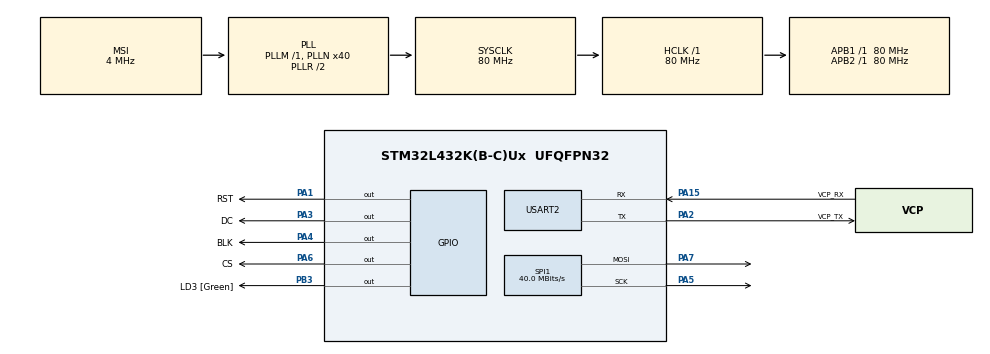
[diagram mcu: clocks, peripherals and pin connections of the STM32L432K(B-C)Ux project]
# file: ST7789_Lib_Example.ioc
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FREERTOS.Tasks01=defaultTask,24,128,StartDefaultTask,Default,NULL,Dynamic,NULL,NULL
FREERTOS.configENABLE_FPU=1
Mcu.Family=STM32L4
Mcu.Name=STM32L432K(B-C)Ux
Mcu.Package=UFQFPN32
NVIC.PriorityGroup=NVIC_PRIORITYGROUP_4
NVIC.TIM1_UP_TIM16_IRQn=true\:15\:0\:false\:false\:true\:false\:false\:true\:true
NVIC.TimeBase=TIM1_UP_TIM16_IRQn
NVIC.TimeBaseIP=TIM1
PA0.GPIO_Label=MCO [High speed clock in]
PA0.Mode=HSE-External-Clock-Source-for-LittleOrca
PA0.Signal=RCC_CK_IN
PA1.GPIO_Label=RST
PA1.Signal=GPIO_Output
PA13\ (JTMS-SWDIO).GPIO_Label=SWDIO
PA13\ (JTMS-SWDIO).Mode=Serial_Wire
PA13\ (JTMS-SWDIO).Signal=SYS_JTMS-SWDIO
PA14\ (JTCK-SWCLK).GPIO_Label=SWCLK
PA14\ (JTCK-SWCLK).Mode=Serial_Wire
PA14\ (JTCK-SWCLK).Signal=SYS_JTCK-SWCLK
PA15\ (JTDI).GPIO_Label=VCP_RX
PA15\ (JTDI).Mode=Asynchronous
PA15\ (JTDI).Signal=USART2_RX
PA2.GPIO_Label=VCP_TX
PA2.Mode=Asynchronous
PA2.Signal=USART2_TX
PA3.GPIO_Label=DC
PA3.Signal=GPIO_Output
PA4.GPIO_Label=BLK
PA4.Signal=GPIO_Output
PA5.Mode=TX_Only_Simplex_Unidirect_Master
PA5.Signal=SPI1_SCK
PA6.GPIO_Label=CS
PA6.Signal=GPIO_Output
PA7.Mode=TX_Only_Simplex_Unidirect_Master
PA7.Signal=SPI1_MOSI
PB3\ (JTDO-TRACESWO).GPIO_Label=LD3 [Green]
PB3\ (JTDO-TRACESWO).Signal=GPIO_Output
PC14-OSC32_IN\ (PC14).Mode=LSE-External-Oscillator
PC14-OSC32_IN\ (PC14).Signal=RCC_OSC32_IN
PC15-OSC32_OUT\ (PC15).Mode=LSE-External-Oscillator
PC15-OSC32_OUT\ (PC15).Signal=RCC_OSC32_OUT
ProjectManager.HeapSize=0x200
ProjectManager.StackSize=0x400
ProjectManager.TargetToolchain=STM32CubeIDE
RCC.ADCFreq_Value=16000000
RCC.AHBFreq_Value=80000000
RCC.APB1Freq_Value=80000000
RCC.APB1TimFreq_Value=80000000
RCC.APB2Freq_Value=80000000
RCC.APB2TimFreq_Value=80000000
RCC.CortexFreq_Value=80000000
RCC.HCLKFreq_Value=80000000
RCC.HSE_VALUE=8000000
RCC.HSI16_VALUE=16000000
RCC.HSI48_VALUE=48000000
RCC.HSI_VALUE=16000000
RCC.MSI_VALUE=4000000
RCC.PLLMUL=RCC_PLLMUL_4
RCC.PLLN=40
RCC.SYSCLKFreq_VALUE=80000000
RCC.SYSCLKSource=RCC_SYSCLKSOURCE_PLLCLK
RCC.USBFreq_Value=16000000
RCC.VCOOutputFreq_Value=160000000
RTC.Date=2
RTC.Month=RTC_MONTH_FEBRUARY
RTC.Year=24
SPI1.BaudRatePrescaler=SPI_BAUDRATEPRESCALER_2
SPI1.CLKPhase=SPI_PHASE_2EDGE
SPI1.CLKPolarity=SPI_POLARITY_HIGH
SPI1.CalculateBaudRate=40.0 MBits/s
SPI1.DataSize=SPI_DATASIZE_8BIT
SPI1.Direction=SPI_DIRECTION_2LINES
SPI1.Mode=SPI_MODE_MASTER
SPI1.VirtualType=VM_MASTER
USART2.VirtualMode-Asynchronous=VM_ASYNC
VP_FREERTOS_VS_CMSIS_V2.Mode=CMSIS_V2
VP_RTC_VS_RTC_Activate.Mode=RTC_Enabled
VP_RTC_VS_RTC_Calendar.Mode=RTC_Calendar
VP_SYS_VS_tim1.Mode=TIM1
board=NUCLEO-L432KC

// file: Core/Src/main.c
/* USER CODE BEGIN Header */
/**
  ******************************************************************************
  * @file           : main.c
  * @brief          : Main program body
  ******************************************************************************
  * @attention
  *
  * Copyright (c) 2024 STMicroelectronics.
  * All rights reserved.
  *
  * This software is licensed under terms that can be found in the LICENSE file
  * in the root directory of this software component.
  * If no LICENSE file comes with this software, it is provided AS-IS.
  *
  ******************************************************************************
  */
/* USER CODE END Header */
#include "main.h"
#include "cmsis_os.h"

/* USER CODE BEGIN Includes */
#include <Interface_ST7789.h>
#include <ST7789.h>
/* USER CODE END Includes */

RTC_HandleTypeDef hrtc;

SPI_HandleTypeDef hspi1;

UART_HandleTypeDef huart2;

/* Definitions for defaultTask */
osThreadId_t defaultTaskHandle;
const osThreadAttr_t defaultTask_attributes = {
  .name = "defaultTask",
  .stack_size = 128 * 4,
  .priority = (osPriority_t) osPriorityNormal,
};

void SystemClock_Config(void);
static void MX_GPIO_Init(void);
static void MX_USART2_UART_Init(void);
static void MX_RTC_Init(void);
static void MX_SPI1_Init(void);
void StartDefaultTask(void *argument);

int main(void)
{

  /* MCU Configuration--------------------------------------------------------*/

  /* Reset of all peripherals, Initializes the Flash interface and the Systick. */
  HAL_Init();

  /* Configure the system clock */
  SystemClock_Config();

  /* Initialize all configured peripherals */
  MX_GPIO_Init();
  MX_USART2_UART_Init();
  MX_RTC_Init();
  MX_SPI1_Init();
  /* USER CODE BEGIN 2 */
  ST7789_Init();
  ST7789_Clear();
  ST7789_FillScreen(ST7789_WHITE);
  osDelay(1000);

  /* USER CODE END 2 */

  /* Init scheduler */
  osKernelInitialize();

  /* Create the thread(s) */
  /* creation of defaultTask */
  defaultTaskHandle = osThreadNew(StartDefaultTask, NULL, &defaultTask_attributes);

  /* Start scheduler */
  osKernelStart();

  /* We should never get here as control is now taken by the scheduler */
  /* Infinite loop */
  while (1)
  {

  }
}

void SystemClock_Config(void)
{
  RCC_OscInitTypeDef RCC_OscInitStruct = {0};
  RCC_ClkInitTypeDef RCC_ClkInitStruct = {0};

  /** Configure the main internal regulator output voltage
  */
  if (HAL_PWREx_ControlVoltageScaling(PWR_REGULATOR_VOLTAGE_SCALE1) != HAL_OK)
  {
    Error_Handler();
  }

  /** Configure LSE Drive Capability
  */
  HAL_PWR_EnableBkUpAccess();
  __HAL_RCC_LSEDRIVE_CONFIG(RCC_LSEDRIVE_LOW);

  /** Initializes the RCC Oscillators according to the specified parameters
  * in the RCC_OscInitTypeDef structure.
  */
  RCC_OscInitStruct.OscillatorType = RCC_OSCILLATORTYPE_LSI|RCC_OSCILLATORTYPE_LSE
                              |RCC_OSCILLATORTYPE_MSI;
  RCC_OscInitStruct.LSEState = RCC_LSE_ON;
  RCC_OscInitStruct.LSIState = RCC_LSI_ON;
  RCC_OscInitStruct.MSIState = RCC_MSI_ON;
  RCC_OscInitStruct.MSICalibrationValue = 0;
  RCC_OscInitStruct.MSIClockRange = RCC_MSIRANGE_6;
  RCC_OscInitStruct.PLL.PLLState = RCC_PLL_ON;
  RCC_OscInitStruct.PLL.PLLSource = RCC_PLLSOURCE_MSI;
  RCC_OscInitStruct.PLL.PLLM = 1;
  RCC_OscInitStruct.PLL.PLLN = 40;
  RCC_OscInitStruct.PLL.PLLP = RCC_PLLP_DIV7;
  RCC_OscInitStruct.PLL.PLLQ = RCC_PLLQ_DIV2;
  RCC_OscInitStruct.PLL.PLLR = RCC_PLLR_DIV2;
  if (HAL_RCC_OscConfig(&RCC_OscInitStruct) != HAL_OK)
  {
    Error_Handler();
  }

  /** Initializes the CPU, AHB and APB buses clocks
  */
  RCC_ClkInitStruct.ClockType = RCC_CLOCKTYPE_HCLK|RCC_CLOCKTYPE_SYSCLK
                              |RCC_CLOCKTYPE_PCLK1|RCC_CLOCKTYPE_PCLK2;
  RCC_ClkInitStruct.SYSCLKSource = RCC_SYSCLKSOURCE_PLLCLK;
  RCC_ClkInitStruct.AHBCLKDivider = RCC_SYSCLK_DIV1;
  RCC_ClkInitStruct.APB1CLKDivider = RCC_HCLK_DIV1;
  RCC_ClkInitStruct.APB2CLKDivider = RCC_HCLK_DIV1;

  if (HAL_RCC_ClockConfig(&RCC_ClkInitStruct, FLASH_LATENCY_4) != HAL_OK)
  {
    Error_Handler();
  }

  /** Enable MSI Auto calibration
  */
  HAL_RCCEx_EnableMSIPLLMode();
}

static void MX_RTC_Init(void)
{

  RTC_TimeTypeDef sTime = {0};
  RTC_DateTypeDef sDate = {0};

  /** Initialize RTC Only
  */
  hrtc.Instance = RTC;
  hrtc.Init.HourFormat = RTC_HOURFORMAT_24;
  hrtc.Init.AsynchPrediv = 127;
  hrtc.Init.SynchPrediv = 255;
  hrtc.Init.OutPut = RTC_OUTPUT_DISABLE;
  hrtc.Init.OutPutRemap = RTC_OUTPUT_REMAP_NONE;
  hrtc.Init.OutPutPolarity = RTC_OUTPUT_POLARITY_HIGH;
  hrtc.Init.OutPutType = RTC_OUTPUT_TYPE_OPENDRAIN;
  if (HAL_RTC_Init(&hrtc) != HAL_OK)
  {
    Error_Handler();
  }

  /** Initialize RTC and set the Time and Date
  */
  sTime.Hours = 0x0;
  sTime.Minutes = 0x0;
  sTime.Seconds = 0x0;
  sTime.DayLightSaving = RTC_DAYLIGHTSAVING_NONE;
  sTime.StoreOperation = RTC_STOREOPERATION_RESET;
  if (HAL_RTC_SetTime(&hrtc, &sTime, RTC_FORMAT_BCD) != HAL_OK)
  {
    Error_Handler();
  }
  sDate.WeekDay = RTC_WEEKDAY_MONDAY;
  sDate.Month = RTC_MONTH_FEBRUARY;
  sDate.Date = 0x2;
  sDate.Year = 0x24;

  if (HAL_RTC_SetDate(&hrtc, &sDate, RTC_FORMAT_BCD) != HAL_OK)
  {
    Error_Handler();
  }

}

static void MX_SPI1_Init(void)
{

  /* SPI1 parameter configuration*/
  hspi1.Instance = SPI1;
  hspi1.Init.Mode = SPI_MODE_MASTER;
  hspi1.Init.Direction = SPI_DIRECTION_2LINES;
  hspi1.Init.DataSize = SPI_DATASIZE_8BIT;
  hspi1.Init.CLKPolarity = SPI_POLARITY_HIGH;
  hspi1.Init.CLKPhase = SPI_PHASE_2EDGE;
  hspi1.Init.NSS = SPI_NSS_SOFT;
  hspi1.Init.BaudRatePrescaler = SPI_BAUDRATEPRESCALER_2;
  hspi1.Init.FirstBit = SPI_FIRSTBIT_MSB;
  hspi1.Init.TIMode = SPI_TIMODE_DISABLE;
  hspi1.Init.CRCCalculation = SPI_CRCCALCULATION_DISABLE;
  hspi1.Init.CRCPolynomial = 7;
  hspi1.Init.CRCLength = SPI_CRC_LENGTH_DATASIZE;
  hspi1.Init.NSSPMode = SPI_NSS_PULSE_DISABLE;
  if (HAL_SPI_Init(&hspi1) != HAL_OK)
  {
    Error_Handler();
  }

}

static void MX_USART2_UART_Init(void)
{

  huart2.Instance = USART2;
  huart2.Init.BaudRate = 115200;
  huart2.Init.WordLength = UART_WORDLENGTH_8B;
  huart2.Init.StopBits = UART_STOPBITS_1;
  huart2.Init.Parity = UART_PARITY_NONE;
  huart2.Init.Mode = UART_MODE_TX_RX;
  huart2.Init.HwFlowCtl = UART_HWCONTROL_NONE;
  huart2.Init.OverSampling = UART_OVERSAMPLING_16;
  huart2.Init.OneBitSampling = UART_ONE_BIT_SAMPLE_DISABLE;
  huart2.AdvancedInit.AdvFeatureInit = UART_ADVFEATURE_NO_INIT;
  if (HAL_UART_Init(&huart2) != HAL_OK)
  {
    Error_Handler();
  }

}

static void MX_GPIO_Init(void)
{
  GPIO_InitTypeDef GPIO_InitStruct = {0};

  /* GPIO Ports Clock Enable */
  __HAL_RCC_GPIOC_CLK_ENABLE();
  __HAL_RCC_GPIOA_CLK_ENABLE();
  __HAL_RCC_GPIOB_CLK_ENABLE();

  /*Configure GPIO pin Output Level */
  HAL_GPIO_WritePin(GPIOA, RST_Pin|DC_Pin|BLK_Pin|CS_Pin, GPIO_PIN_RESET);

  /*Configure GPIO pin Output Level */
  HAL_GPIO_WritePin(LD3_GPIO_Port, LD3_Pin, GPIO_PIN_RESET);

  /*Configure GPIO pins : RST_Pin DC_Pin BLK_Pin CS_Pin */
  GPIO_InitStruct.Pin = RST_Pin|DC_Pin|BLK_Pin|CS_Pin;
  GPIO_InitStruct.Mode = GPIO_MODE_OUTPUT_PP;
  GPIO_InitStruct.Pull = GPIO_NOPULL;
  GPIO_InitStruct.Speed = GPIO_SPEED_FREQ_LOW;
  HAL_GPIO_Init(GPIOA, &GPIO_InitStruct);

  /*Configure GPIO pin : LD3_Pin */
  GPIO_InitStruct.Pin = LD3_Pin;
  GPIO_InitStruct.Mode = GPIO_MODE_OUTPUT_PP;
  GPIO_InitStruct.Pull = GPIO_NOPULL;
  GPIO_InitStruct.Speed = GPIO_SPEED_FREQ_LOW;
  HAL_GPIO_Init(LD3_GPIO_Port, &GPIO_InitStruct);

}

void StartDefaultTask(void *argument)
{
  /* USER CODE BEGIN 5 */
  /* Infinite loop */
  for(;;)
  {
	ST7789_FillScreen( ST7789_BLUE);
    //osDelay(1000);
    ST7789_FillScreen( ST7789_RED );
    //osDelay(1000);
    ST7789_FillScreen( ST7789_GREEN );
   // osDelay(1000);
  }
  /* USER CODE END 5 */
}

void HAL_TIM_PeriodElapsedCallback(TIM_HandleTypeDef *htim)
{
  if (htim->Instance == TIM1) {
    HAL_IncTick();
  }
}

void Error_Handler(void)
{
  __disable_irq();
  while (1)
  {
  }
}
